# irq_ctrl: IP-XACT component
VLNV ssd-soc:cpu_ss:irq_ctrl:1.0.0

## Ports
in clk
in rst_n
in irq_src_i[31:0]
out eip_o
out eip_id_o[4:0]

## Address spaces and blocks
regs.irq_ctrl_regs: base 0x0, range 4096, width 32, register

## Registers
Registers are 32-bit, read-only, reset 0x0 unless marked. A register's access mark holds for its fields unless they carry their own. Offsets are from the block's base; lines under a group give offsets from that group; [hi:lo] are bit positions; {n}, {i} and the like mark numbered series; 'fields as' and 'values as' point back to an identical list; <NAME> marks a mode.

## regs.irq_ctrl_regs
Base 0x00000000
0x00 PRIORITY_0 — 예약된 source-0 priority (항상 0).
  [3:0] VALUE
{0x4+4i} PRIORITY[{i}] (i=0..30) rw — source별 priority. 0=disabled, 1..15=active.
  [3:0] VALUE — source N의 priority 값 (PRIORITY[N], N=1..31).
0x100 PENDING — source별 pending. 비트 i = source i pending. 비트 0은 예약 (=0).
  [31:0] BITS
0x104 PENDING_CLEAR wo — 1 write 시 pending 비트 clear (edge source 전용). Read는 0.
  [31:0] BITS write-1-clears
0x200 ENABLE rw — source별 enable. 비트 i = source i 해제. 비트 0은 예약 (=0).
  [31:0] BITS
0x300 THRESHOLD rw — 전역 priority threshold. source는 priority > threshold일 때만 fire.
  [3:0] VALUE
0x304 CLAIM_COMPLETE rw — Read: winning source ID 반환 및 해당 source pending atomic clear (edge source 전용). Write: 완료 ack (v1.0에서는 informational; 향후 multi-context gating용으로 예약).
  [4:0] ID read-clears — Interrupt source ID (1..31). 0 = eligible pending source 없음.
0x308 IP_ID reset 0x49524301 — IP 식별자 상수 ("IRC\1" = 0x49524301).
  [31:0] VALUE
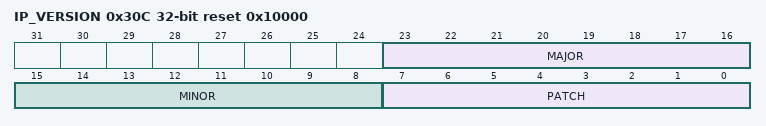
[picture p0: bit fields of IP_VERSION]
0x30C IP_VERSION reset 0x10000 — Version 상수: {major[15:8], minor[7:0], patch[7:0]} = 1.0.0.
  [23:16] MAJOR, [15:8] MINOR, [7:0] PATCH
